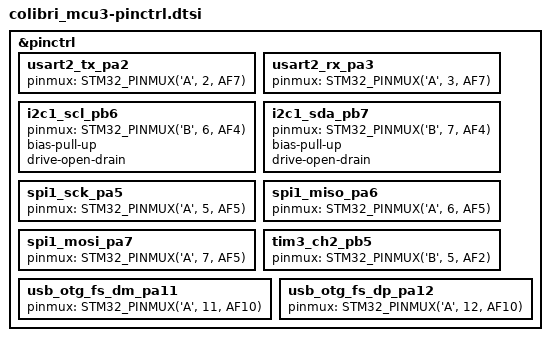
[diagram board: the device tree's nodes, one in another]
#include <zephyr/dt-bindings/pinctrl/stm32-pinctrl.h>

&pinctrl {
	/* USART2: Debugger Pins */
	usart2_tx_pa2: usart2_tx_pa2 {
		pinmux = <STM32_PINMUX('A', 2, AF7)>;
	};
	usart2_rx_pa3: usart2_rx_pa3 {
		pinmux = <STM32_PINMUX('A', 3, AF7)>;
	};

	/* I2C1: Carrier Bus */
	i2c1_scl_pb6: i2c1_scl_pb6 {
		pinmux = <STM32_PINMUX('B', 6, AF4)>;
		bias-pull-up;
		drive-open-drain;
	};
	i2c1_sda_pb7: i2c1_sda_pb7 {
		pinmux = <STM32_PINMUX('B', 7, AF4)>;
		bias-pull-up;
		drive-open-drain;
	};

	/* SPI1: Flash and Carrier SPI */
	spi1_sck_pa5: spi1_sck_pa5 {
		pinmux = <STM32_PINMUX('A', 5, AF5)>;
	};
	spi1_miso_pa6: spi1_miso_pa6 {
		pinmux = <STM32_PINMUX('A', 6, AF5)>;
	};
	spi1_mosi_pa7: spi1_mosi_pa7 {
		pinmux = <STM32_PINMUX('A', 7, AF5)>;
	};

	/* PWM for WS2812 on PB5 */
	tim3_ch2_pb5: tim3_ch2_pb5 {
		pinmux = <STM32_PINMUX('B', 5, AF2)>;
	};

	/* USB OTG FS */
	usb_otg_fs_dm_pa11: usb_otg_fs_dm_pa11 {
		pinmux = <STM32_PINMUX('A', 11, AF10)>;
	};
	usb_otg_fs_dp_pa12: usb_otg_fs_dp_pa12 {
		pinmux = <STM32_PINMUX('A', 12, AF10)>;
	};
};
